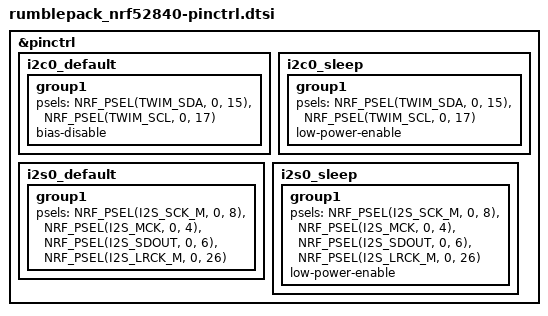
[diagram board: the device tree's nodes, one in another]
&pinctrl{
    i2c0_default: i2c0_default {
		group1 {
			psels = <NRF_PSEL(TWIM_SDA, 0, 15)>,
				    <NRF_PSEL(TWIM_SCL, 0, 17)>;
            bias-disable;
		};
	};

	i2c0_sleep: i2c0_sleep {
		group1 {
			psels = <NRF_PSEL(TWIM_SDA, 0, 15)>,
				    <NRF_PSEL(TWIM_SCL, 0, 17)>;
			low-power-enable;
		};
	};

    i2s0_default: i2s0_default {
        group1 {
            psels = <NRF_PSEL(I2S_SCK_M, 0, 8)>,
                    <NRF_PSEL(I2S_MCK, 0, 4)>,
                    <NRF_PSEL(I2S_SDOUT, 0, 6)>,
                    <NRF_PSEL(I2S_LRCK_M, 0, 26)>;
        };
    };
    i2s0_sleep: i2s0_sleep {
        group1 {
            psels = <NRF_PSEL(I2S_SCK_M, 0, 8)>,
                    <NRF_PSEL(I2S_MCK, 0, 4)>,
                    <NRF_PSEL(I2S_SDOUT, 0, 6)>,
                    <NRF_PSEL(I2S_LRCK_M, 0, 26)>;
            low-power-enable;
        };
    };
};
